# STM32F40x register map
File version: 1.5
Registers are 32-bit, read-write, reset 0x0 unless marked. A register's access mark holds for its fields unless they carry their own. Offsets are from the block's base; [hi:lo] are bit positions.

## WWDG（窗口看门狗） — 窗口看门狗：窗口内喂狗否则复位 | Window watchdog
Base 0x40002C00
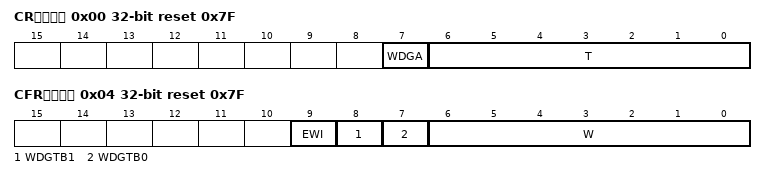
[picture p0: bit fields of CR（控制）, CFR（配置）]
0x00 CR（控制） reset 0x7F — 控制：使能/计数器（含窗口位） | Control register
  [7] WDGA — Activation bit
  [6:0] T — 7-bit counter (MSB to LSB)
0x04 CFR（配置） reset 0x7F — 配置：窗口值/预分频/提前唤醒中断 | Configuration register
  [9] EWI — Early wakeup interrupt
  [8] WDGTB1 — Timer base
  [7] WDGTB0 — Timer base
  [6:0] W — 7-bit window value
0x08 SR（状态） — 状态：提前唤醒中断标志 | Status register
  [0] EWIF — Early wakeup interrupt flag

## UART4（串口4） — 通用异步收发器：异步串行通信 | Universal synchronous asynchronous receiver transmitter
Base 0x40004C00
Same registers: UART5（串口5） 0x40005000
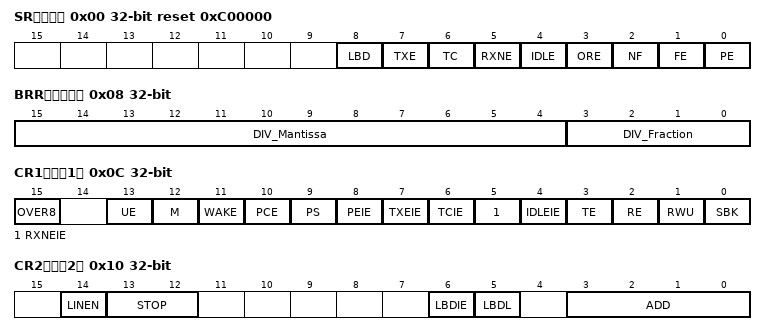
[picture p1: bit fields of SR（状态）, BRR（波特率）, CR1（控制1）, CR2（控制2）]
0x00 SR（状态） access per field reset 0xC00000 — 状态：发送/接收就绪与各种错误/中断标志 | Status register
  [8] LBD rw — LIN break detection flag
  [7] TXE ro — Transmit data register empty
  [6] TC rw — Transmission complete
  [5] RXNE rw — Read data register not empty
  [4] IDLE ro — IDLE line detected
  [3] ORE ro — Overrun error
  [2] NF ro — Noise detected flag
  [1] FE ro — Framing error
  [0] PE ro — Parity error
0x04 DR（数据） — 数据：发送/接收数据寄存器 | Data register
  [8:0] DR — Data value
0x08 BRR（波特率） — 波特率：波特率分频系数 | Baud rate register
  [15:4] DIV_Mantissa — mantissa of USARTDIV
  [3:0] DIV_Fraction — fraction of USARTDIV
0x0C CR1（控制1） — 控制1：使能/字长/校验/中断/收发主控制 | Control register 1
  [15] OVER8 — Oversampling mode
  [13] UE — USART enable
  [12] M — Word length
  [11] WAKE — Wakeup method
  [10] PCE — Parity control enable
  [9] PS — Parity selection
  [8] PEIE — PE interrupt enable
  [7] TXEIE — TXE interrupt enable
  [6] TCIE — Transmission complete interrupt enable
  [5] RXNEIE — RXNE interrupt enable
  [4] IDLEIE — IDLE interrupt enable
  [3] TE — Transmitter enable
  [2] RE — Receiver enable
  [1] RWU — Receiver wakeup
  [0] SBK — Send break
0x10 CR2（控制2） — 控制2：停止位/时钟/地址/红外等 | Control register 2
  [14] LINEN — LIN mode enable
  [13:12] STOP — STOP bits
  [6] LBDIE — LIN break detection interrupt enable
  [5] LBDL — lin break detection length
  [3:0] ADD — Address of the USART node
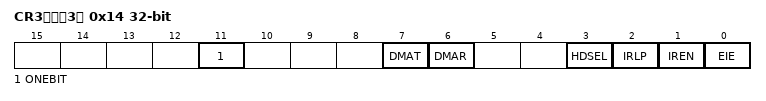
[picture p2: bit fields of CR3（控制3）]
0x14 CR3（控制3） — 控制3：硬件流控/DMA/智能卡纠错 | Control register 3
  [11] ONEBIT — One sample bit method enable
  [7] DMAT — DMA enable transmitter
  [6] DMAR — DMA enable receiver
  [3] HDSEL — Half-duplex selection
  [2] IRLP — IrDA low-power
  [1] IREN — IrDA mode enable
  [0] EIE — Error interrupt enable

## C_ADC（ADC公共） — ADC 公共寄存器：多 ADC 模式与采样控制 | Common ADC registers
Base 0x40012300
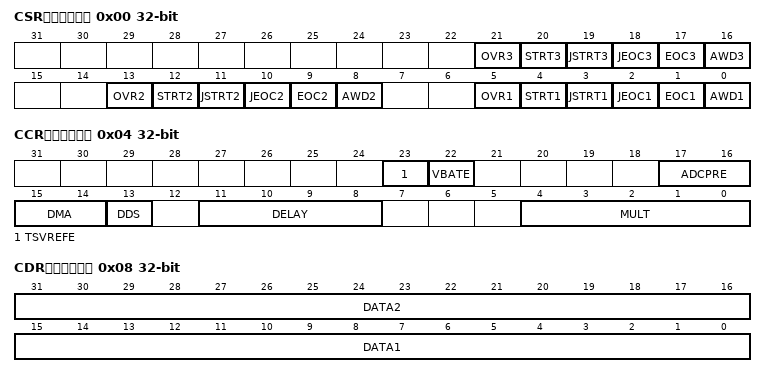
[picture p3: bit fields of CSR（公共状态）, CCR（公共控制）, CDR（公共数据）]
0x00 CSR（公共状态） ro — 公共状态：多 ADC 状态 | ADC Common status register
  [21] OVR3 — Overrun flag of ADC3
  [20] STRT3 — Regular channel Start flag of ADC 3
  [19] JSTRT3 — Injected channel Start flag of ADC 3
  [18] JEOC3 — Injected channel end of conversion of ADC 3
  [17] EOC3 — End of conversion of ADC 3
  [16] AWD3 — Analog watchdog flag of ADC 3
  [13] OVR2 — Overrun flag of ADC 2
  [12] STRT2 — Regular channel Start flag of ADC 2
  [11] JSTRT2 — Injected channel Start flag of ADC 2
  [10] JEOC2 — Injected channel end of conversion of ADC 2
  [9] EOC2 — End of conversion of ADC 2
  [8] AWD2 — Analog watchdog flag of ADC 2
  [5] OVR1 — Overrun flag of ADC 1
  [4] STRT1 — Regular channel Start flag of ADC 1
  [3] JSTRT1 — Injected channel Start flag of ADC 1
  [2] JEOC1 — Injected channel end of conversion of ADC 1
  [1] EOC1 — End of conversion of ADC 1
  [0] AWD1 — Analog watchdog flag of ADC 1
0x04 CCR（公共控制） — 公共控制：多 ADC 模式/采样延迟/温度/Vbat | ADC common control register
  [23] TSVREFE — Temperature sensor and VREFINT enable
  [22] VBATE — VBAT enable
  [17:16] ADCPRE — ADC prescaler
  [15:14] DMA — Direct memory access mode for multi ADC mode
  [13] DDS — DMA disable selection for multi-ADC mode
  [11:8] DELAY — Delay between 2 sampling phases
  [4:0] MULT — Multi ADC mode selection
0x08 CDR（公共数据） ro — 公共数据：双 ADC 交替数据 | ADC common regular data register for dual and triple modes
  [31:16] DATA2 — 2nd data item of a pair of regular conversions
  [15:0] DATA1 — 1st data item of a pair of regular conversions
